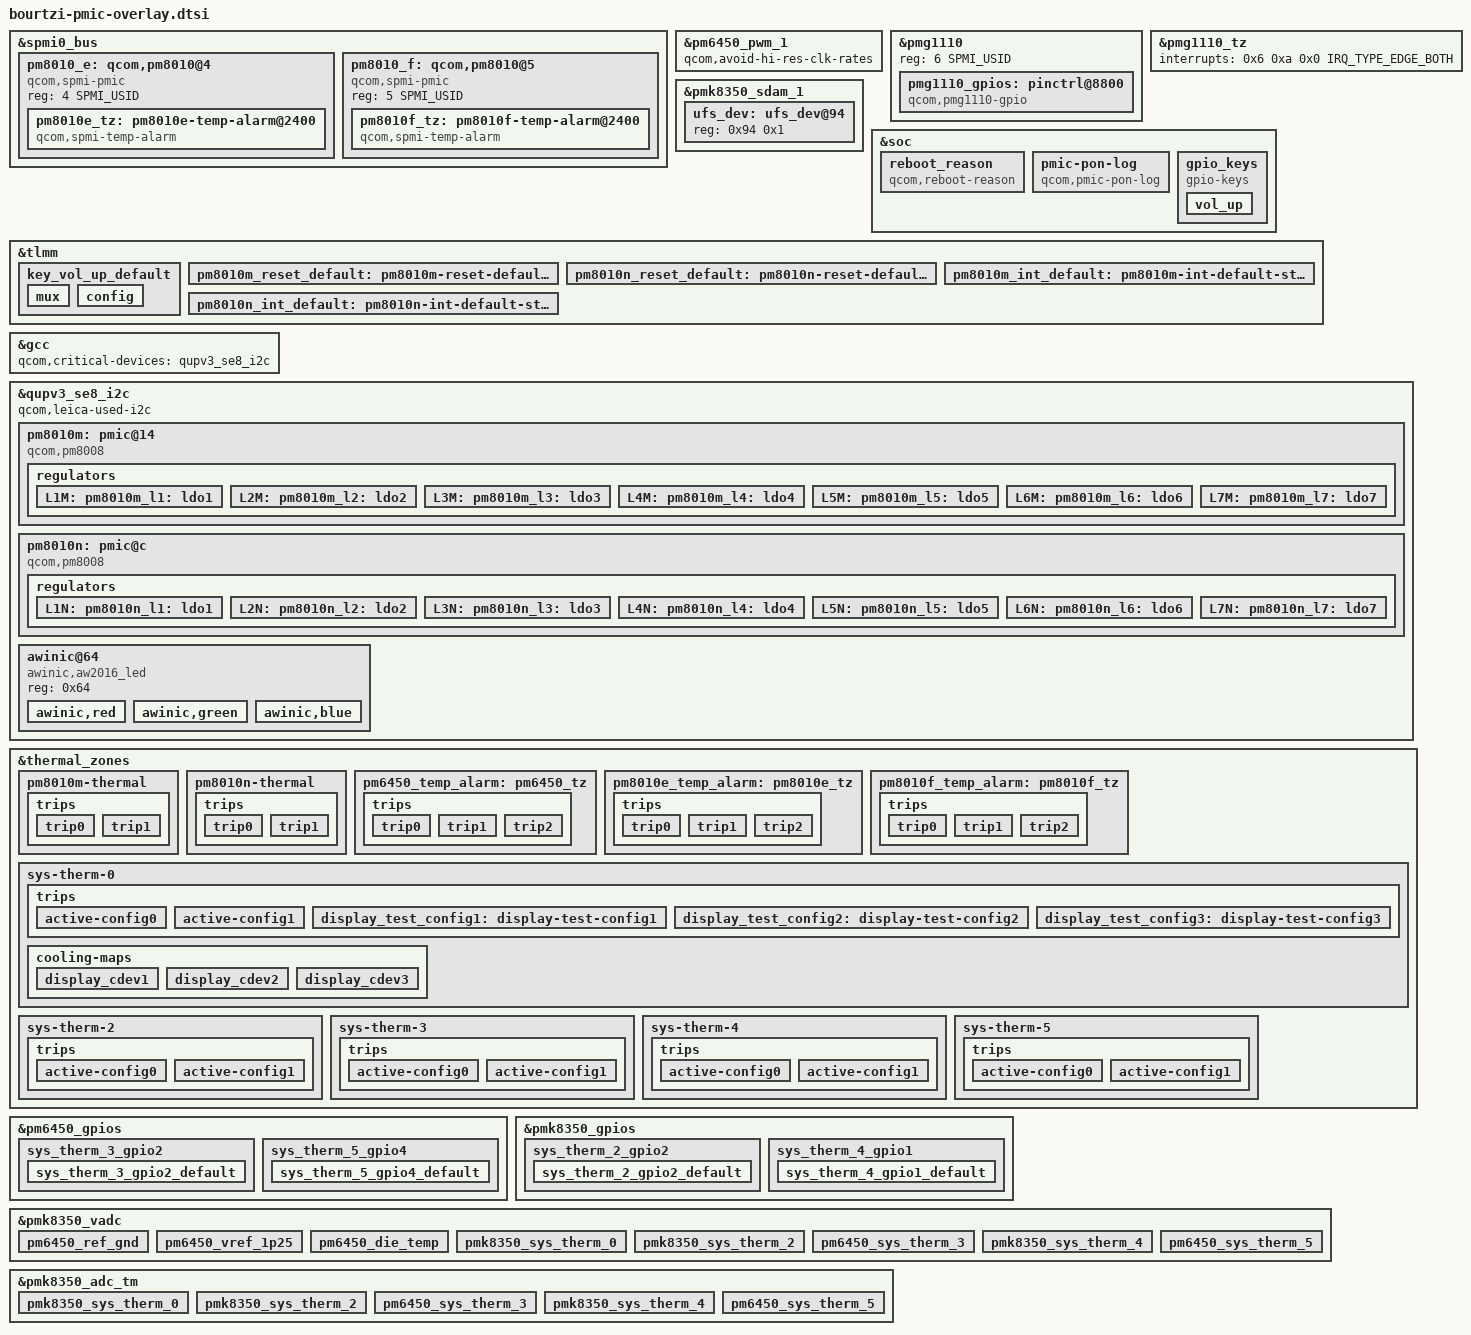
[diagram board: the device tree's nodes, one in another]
// SPDX-License-Identifier: BSD-3-Clause
/*
 * Copyright (c) Qualcomm Technologies, Inc. and/or its subsidiaries.
 */

#include <dt-bindings/gpio/gpio.h>
#include <dt-bindings/iio/qcom,spmi-adc7-pm6450.h>
#include <dt-bindings/interrupt-controller/irq.h>
#include <dt-bindings/pinctrl/qcom,pmic-gpio.h>

#include "pmk8350.dtsi"

&spmi0_bus {
	#include "pm6450.dtsi"
	#include "pmg1110.dtsi"

	pm8010_e: qcom,pm8010@4 {
		compatible = "qcom,spmi-pmic";
		reg = <4 SPMI_USID>;
		#address-cells = <1>;
		#size-cells = <0>;

		pm8010e_tz: pm8010e-temp-alarm@2400 {
			compatible = "qcom,spmi-temp-alarm";
			reg = <0x2400>;
			interrupts = <0x4 0x24 0x0 IRQ_TYPE_EDGE_BOTH>;
			#thermal-sensor-cells = <0>;
		};
	};

	pm8010_f: qcom,pm8010@5 {
		compatible = "qcom,spmi-pmic";
		reg = <5 SPMI_USID>;
		#address-cells = <1>;
		#size-cells = <0>;

		pm8010f_tz: pm8010f-temp-alarm@2400 {
			compatible = "qcom,spmi-temp-alarm";
			reg = <0x2400>;
			interrupts = <0x5 0x24 0x0 IRQ_TYPE_EDGE_BOTH>;
			#thermal-sensor-cells = <0>;
		};
	};
};

&pm6450_pwm_1 {
	status = "okay";
	qcom,avoid-hi-res-clk-rates;
};

&pmg1110 {
	reg = <6 SPMI_USID>;

	pmg1110_gpios: pinctrl@8800 {
		compatible = "qcom,pmg1110-gpio";
		reg = <0x8800>;
		gpio-controller;
		#gpio-cells = <2>;
		interrupt-controller;
		#interrupt-cells = <2>;
	};
};

&pmg1110_tz {
	interrupts = <0x6 0xa 0x0 IRQ_TYPE_EDGE_BOTH>;
};

&pmk8350_sdam_1 {
	ufs_dev: ufs_dev@94 {
		reg = <0x94 0x1>;
	 };
};

&soc {
	reboot_reason {
		compatible = "qcom,reboot-reason";
		nvmem-cells = <&restart_reason>;
		nvmem-cell-names = "restart_reason";
	};

	pmic-pon-log {
		compatible = "qcom,pmic-pon-log";
		nvmem = <&pmk8350_sdam_5>;
		nvmem-names = "pon_log";
	};

	gpio_keys {
		compatible = "gpio-keys";
		label = "gpio-keys";

		pinctrl-names = "default";
		pinctrl-0 = <&key_vol_up_default>;

		vol_up {
			label = "volume_up";
			gpios = <&tlmm 53 GPIO_ACTIVE_LOW>;
			linux,input-type = <1>;
			linux,code = <KEY_VOLUMEUP>;
			gpio-key,wakeup;
			debounce-interval = <15>;
			linux,can-disable;
		};
	};
};

&tlmm {
	key_vol_up_default: key_vol_up_default {
		mux {
			pins = "gpio53";
			function = "gpio";
		};

		config {
			pins = "gpio53";
			drive-strength = <2>;
			bias-pull-up;
			input-enable;
		};
	};

	pm8010m_reset_default: pm8010m-reset-default-state {
		pins = "gpio59";
		function = "gpio";
		bias-pull-down;
	};

	pm8010n_reset_default: pm8010n-reset-default-state {
		pins = "gpio30";
		function = "gpio";
		bias-pull-down;
	};

	pm8010m_int_default: pm8010m-int-default-state {
		pins = "gpio62";
		function = "gpio";
		drive-strength = <2>;
		bias-disable;
	};

	pm8010n_int_default: pm8010n-int-default-state {
		pins = "gpio28";
		function = "gpio";
		drive-strength = <2>;
		bias-disable;
	};
};

&gcc {
	qcom,critical-devices = <&qupv3_se8_i2c>;
};

&qupv3_se8_i2c {
	#address-cells = <1>;
	#size-cells = <0>;
	status = "okay";
	qcom,leica-used-i2c;

	pm8010m: pmic@14 {
		compatible = "qcom,pm8008";
		reg = <0x14>;

		interrupts-extended = <&tlmm 62 IRQ_TYPE_EDGE_RISING>;
		reset-gpios = <&tlmm 59 GPIO_ACTIVE_LOW>;

		pinctrl-names = "default";
		pinctrl-0 = <&pm8010m_int_default>, <&pm8010m_reset_default>;

		gpio-controller;
		#gpio-cells = <2>;
		gpio-ranges = <&pm8010m 0 0 2>;

		interrupt-controller;
		#interrupt-cells = <2>;

		#thermal-sensor-cells = <0>;

		regulators {
			L1M: pm8010m_l1: ldo1 {
				regulator-name = "pm8010m_l1";
				regulator-min-microvolt = <1056000>;
				regulator-max-microvolt = <1184000>;
			};

			L2M: pm8010m_l2: ldo2 {
				regulator-name = "pm8010m_l2";
				regulator-min-microvolt = <952000>;
				regulator-max-microvolt = <1152000>;
			};

			L3M: pm8010m_l3: ldo3 {
				regulator-name = "pm8010m_l3";
				regulator-min-microvolt = <2704000>;
				regulator-max-microvolt = <2904000>;
			};

			L4M: pm8010m_l4: ldo4 {
				regulator-name = "pm8010m_l4";
				regulator-min-microvolt = <2704000>;
				regulator-max-microvolt = <2904000>;
			};

			L5M: pm8010m_l5: ldo5 {
				regulator-name = "pm8010m_l5";
				regulator-min-microvolt = <1504000>;
				regulator-max-microvolt = <3544000>;
			};

			L6M: pm8010m_l6: ldo6 {
				regulator-name = "pm8010m_l6";
				regulator-min-microvolt = <2704000>;
				regulator-max-microvolt = <2904000>;
			};

			L7M: pm8010m_l7: ldo7 {
				regulator-name = "pm8010m_l7";
				regulator-min-microvolt = <2704000>;
				regulator-max-microvolt = <3000000>;
			};
		};
	};

	pm8010n: pmic@c {
		compatible = "qcom,pm8008";
		reg = <0xc>;

		interrupts-extended = <&tlmm 28 IRQ_TYPE_EDGE_RISING>;
		reset-gpios = <&tlmm 30 GPIO_ACTIVE_LOW>;

		pinctrl-names = "default";
		pinctrl-0 = <&pm8010n_int_default>, <&pm8010n_reset_default>;

		gpio-controller;
		#gpio-cells = <2>;
		gpio-ranges = <&pm8010n 0 0 2>;

		interrupt-controller;
		#interrupt-cells = <2>;

		#thermal-sensor-cells = <0>;

		regulators {
			L1N: pm8010n_l1: ldo1 {
				regulator-name = "pm8010n_l1";
				regulator-min-microvolt = <1056000>;
				regulator-max-microvolt = <1200000>;
			};

			L2N: pm8010n_l2: ldo2 {
				regulator-name = "pm8010n_l2";
				regulator-min-microvolt = <952000>;
				regulator-max-microvolt = <1152000>;
			};

			L3N: pm8010n_l3: ldo3 {
				regulator-name = "pm8010n_l3";
				regulator-min-microvolt = <1792000>;
				regulator-max-microvolt = <1904000>;
			};

			L4N: pm8010n_l4: ldo4 {
				regulator-name = "pm8010n_l4";
				regulator-min-microvolt = <1792000>;
				regulator-max-microvolt = <1904000>;
			};

			L5N: pm8010n_l5: ldo5 {
				regulator-name = "pm8010n_l5";
				regulator-min-microvolt = <1504000>;
				regulator-max-microvolt = <3544000>;
			};

			L6N: pm8010n_l6: ldo6 {
				regulator-name = "pm8010n_l6";
				regulator-min-microvolt = <2704000>;
				regulator-max-microvolt = <2904000>;
			};

			L7N: pm8010n_l7: ldo7 {
				regulator-name = "pm8010n_l7";
				regulator-min-microvolt = <1504000>;
				regulator-max-microvolt = <3544000>;
			};
		};
	};

	awinic@64 {
		compatible = "awinic,aw2016_led";
		reg = <0x64>;

		awinic,red {
			awinic,name = "red";
			awinic,id = <0>;
			awinic,imax = <2>;
			awinic,led-current = <3>;
			awinic,max-brightness = <255>;
			awinic,rise-time-ms = <6>;
			awinic,hold-time-ms = <0>;
			awinic,fall-time-ms = <6>;
			awinic,off-time-ms = <4>;
		};

		awinic,green {
			awinic,name = "green";
			awinic,id = <1>;
			awinic,imax = <2>;
			awinic,led-current = <3>;
			awinic,max-brightness = <255>;
			awinic,rise-time-ms = <6>;
			awinic,hold-time-ms = <0>;
			awinic,fall-time-ms = <6>;
			awinic,off-time-ms = <4>;
		};

		awinic,blue {
			awinic,name = "blue";
			awinic,id = <2>;
			awinic,imax = <2>;
			awinic,led-current = <3>;
			awinic,max-brightness = <255>;
			awinic,rise-time-ms = <6>;
			awinic,hold-time-ms = <0>;
			awinic,fall-time-ms = <6>;
			awinic,off-time-ms = <4>;
		};
	};
};

&thermal_zones {
	pm8010m-thermal {
		polling-delay-passive = <100>;
		polling-delay = <0>;
		thermal-sensors = <&pm8010m>;

		trips {
			trip0 {
				temperature = <95000>;
				hysteresis = <0>;
				type = "passive";
			};

			trip1 {
				temperature = <115000>;
				hysteresis = <0>;
				type = "critical";
			};
		};
	};

	pm8010n-thermal {
		polling-delay-passive = <100>;
		polling-delay = <0>;
		thermal-sensors = <&pm8010n>;

		trips {
			trip0 {
				temperature = <95000>;
				hysteresis = <0>;
				type = "passive";
			};

			trip1 {
				temperature = <115000>;
				hysteresis = <0>;
				type = "critical";
			};
		};
	};

	pm6450_temp_alarm: pm6450_tz {
		polling-delay-passive = <100>;
		thermal-sensors = <&pm6450_tz>;

		trips {
			trip0 {
				temperature = <95000>;
				hysteresis = <0>;
				type = "passive";
			};

			trip1 {
				temperature = <115000>;
				hysteresis = <0>;
				type = "hot";
			};

			trip2 {
				temperature = <145000>;
				hysteresis = <0>;
				type = "critical";
			};
		};
	};

	pm8010e_temp_alarm: pm8010e_tz {
		polling-delay-passive = <100>;
		thermal-sensors = <&pm8010e_tz>;

		trips {
			trip0 {
				temperature = <95000>;
				hysteresis = <0>;
				type = "passive";
			};

			trip1 {
				temperature = <115000>;
				hysteresis = <0>;
				type = "hot";
			};

			trip2 {
				temperature = <145000>;
				hysteresis = <0>;
				type = "critical";
			};
		};
	};

	pm8010f_temp_alarm: pm8010f_tz {
		polling-delay-passive = <100>;
		thermal-sensors = <&pm8010f_tz>;

		trips {
			trip0 {
				temperature = <95000>;
				hysteresis = <0>;
				type = "passive";
			};

			trip1 {
				temperature = <115000>;
				hysteresis = <0>;
				type = "hot";
			};

			trip2 {
				temperature = <145000>;
				hysteresis = <0>;
				type = "critical";
			};
		};
	};

	sys-therm-0 {
		polling-delay-passive = <0>;
		thermal-sensors = <&pmk8350_adc_tm 0>;

		trips {
			active-config0 {
				temperature = <125000>;
				hysteresis = <1000>;
				type = "passive";
			};

			active-config1 {
				temperature = <125000>;
				hysteresis = <1000>;
				type = "passive";
			};

			display_test_config1: display-test-config1 {
				temperature = <125000>;
				hysteresis = <1000>;
				type = "passive";
			};

			display_test_config2: display-test-config2 {
				temperature = <125000>;
				hysteresis = <1000>;
				type = "passive";
			};

			display_test_config3: display-test-config3 {
				temperature = <125000>;
				hysteresis = <1000>;
				type = "passive";
			};
		};

		cooling-maps {
			display_cdev1 {
				trip = <&display_test_config1>;
				cooling-device = <&display_fps 1 1>;
			};

			display_cdev2 {
				trip = <&display_test_config2>;
				cooling-device = <&display_fps 2 2>;
			};

			display_cdev3 {
				trip = <&display_test_config3>;
				cooling-device = <&display_fps 3 3>;
			};
		};
	};

	sys-therm-2 {
		polling-delay-passive = <0>;
		thermal-sensors = <&pmk8350_adc_tm 2>;

		trips {
			active-config0 {
				temperature = <125000>;
				hysteresis = <1000>;
				type = "passive";
			};

			active-config1 {
				temperature = <125000>;
				hysteresis = <1000>;
				type = "passive";
			};
		};
	};

	sys-therm-3 {
		polling-delay-passive = <0>;
		thermal-sensors = <&pmk8350_adc_tm 3>;

		trips {
			active-config0 {
				temperature = <125000>;
				hysteresis = <1000>;
				type = "passive";
			};

			active-config1 {
				temperature = <125000>;
				hysteresis = <1000>;
				type = "passive";
			};
		};
	};

	sys-therm-4 {
		polling-delay-passive = <0>;
		thermal-sensors = <&pmk8350_adc_tm 4>;

		trips {
			active-config0 {
				temperature = <125000>;
				hysteresis = <1000>;
				type = "passive";
			};

			active-config1 {
				temperature = <125000>;
				hysteresis = <1000>;
				type = "passive";
			};
		};
	};

	sys-therm-5 {
		polling-delay-passive = <0>;
		thermal-sensors = <&pmk8350_adc_tm 5>;

		trips {
			active-config0 {
				temperature = <125000>;
				hysteresis = <1000>;
				type = "passive";
			};

			active-config1 {
				temperature = <125000>;
				hysteresis = <1000>;
				type = "passive";
			};
		};
	};
};

&pm6450_gpios {
	sys_therm_3_gpio2 {
		sys_therm_3_gpio2_default: sys_therm_3_gpio2_default {
			pins = "gpio2";
			bias-high-impedance;
		};
	};

	sys_therm_5_gpio4 {
		sys_therm_5_gpio4_default: sys_therm_5_gpio4_default {
			pins = "gpio4";
			bias-high-impedance;
		};
	};
};

&pmk8350_gpios {
	sys_therm_2_gpio2 {
		sys_therm_2_gpio2_default: sys_therm_2_gpio2_default {
			pins = "gpio2";
			bias-high-impedance;
		};
	};

	sys_therm_4_gpio1 {
		sys_therm_4_gpio1_default: sys_therm_4_gpio1_default {
			pins = "gpio1";
			bias-high-impedance;
		};
	};
};

&pmk8350_vadc {
	pinctrl-names = "default";
	pinctrl-0 = <&sys_therm_2_gpio2_default>,
		    <&sys_therm_3_gpio2_default>,
		    <&sys_therm_4_gpio1_default>,
		    <&sys_therm_5_gpio4_default>;

	/delete-node/ pmk8350_xo_therm;
	/delete-node/ pm8350_ref_gnd;
	/delete-node/ pm8350_vref_1p25;
	/delete-node/ pm8350_die_temp;
	/delete-node/ pm8350_vph_pwr;

	/delete-node/ pm8350b_ref_gnd;
	/delete-node/ pm8350b_vref_1p25;
	/delete-node/ pm8350b_die_temp;
	/delete-node/ pm8350b_vph_pwr;
	/delete-node/ pm8350b_vbat_sns;

	/delete-node/ pmr735a_ref_gnd;
	/delete-node/ pmr735a_vref_1p25;
	/delete-node/ pmr735a_die_temp;

	/delete-node/ pmr735b_ref_gnd;
	/delete-node/ pmr735b_vref_1p25;
	/delete-node/ pmr735b_die_temp;

	/* PM6450 Channel nodes */
	pm6450_ref_gnd {
		reg = <PM6450_ADC7_REF_GND>;
		label = "pm6450_ref_gnd";
		qcom,pre-scaling = <1 1>;
	};

	pm6450_vref_1p25 {
		reg = <PM6450_ADC7_1P25VREF>;
		label = "pm6450_vref_1p25";
		qcom,pre-scaling = <1 1>;
	};

	pm6450_die_temp {
		reg = <PM6450_ADC7_DIE_TEMP>;
		label = "pm6450_die_temp";
		qcom,pre-scaling = <1 1>;
	};

	pmk8350_sys_therm_0 {
		reg = <PMK8350_ADC7_AMUX_THM1_100K_PU>;
		label = "pmk8350_sys_therm_0";
		qcom,ratiometric;
		qcom,hw-settle-time = <200>;
		qcom,pre-scaling = <1 1>;
	};

	pmk8350_sys_therm_2 {
		reg = <PMK8350_ADC7_AMUX_THM3_100K_PU>;
		label = "pmk8350_sys_therm_2";
		qcom,ratiometric;
		qcom,hw-settle-time = <200>;
		qcom,pre-scaling = <1 1>;
	};

	pm6450_sys_therm_3 {
		reg = <PM6450_ADC7_AMUX1_GPIO2_100K_PU>;
		label = "pm6450_sys_therm_3";
		qcom,ratiometric;
		qcom,hw-settle-time = <200>;
		qcom,pre-scaling = <1 1>;
	};

	pmk8350_sys_therm_4 {
		reg = <PMK8350_ADC7_AMUX_THM2_100K_PU>;
		label = "pmk8350_sys_therm_4";
		qcom,ratiometric;
		qcom,hw-settle-time = <200>;
		qcom,pre-scaling = <1 1>;
	};

	pm6450_sys_therm_5 {
		reg = <PM6450_ADC7_AMUX3_GPIO4_100K_PU>;
		label = "pm6450_sys_therm_5";
		qcom,ratiometric;
		qcom,hw-settle-time = <200>;
		qcom,pre-scaling = <1 1>;
	};
};

&pmk8350_adc_tm {
	pmk8350_sys_therm_0 {
		reg = <0>;
		io-channels = <&pmk8350_vadc PMK8350_ADC7_AMUX_THM1_100K_PU>;
		qcom,ratiometric;
		qcom,hw-settle-time-us = <200>;
	};

	pmk8350_sys_therm_2 {
		reg = <2>;
		io-channels = <&pmk8350_vadc PMK8350_ADC7_AMUX_THM3_100K_PU>;
		qcom,ratiometric;
		qcom,hw-settle-time-us = <200>;
	};

	pm6450_sys_therm_3 {
		reg = <3>;
		io-channels = <&pmk8350_vadc PM6450_ADC7_AMUX1_GPIO2_100K_PU>;
		qcom,ratiometric;
		qcom,hw-settle-time-us = <200>;
	};

	pmk8350_sys_therm_4 {
		reg = <4>;
		io-channels = <&pmk8350_vadc PMK8350_ADC7_AMUX_THM2_100K_PU>;
		qcom,ratiometric;
		qcom,hw-settle-time-us = <200>;
	};

	pm6450_sys_therm_5 {
		reg = <5>;
		io-channels = <&pmk8350_vadc PM6450_ADC7_AMUX3_GPIO4_100K_PU>;
		qcom,ratiometric;
		qcom,hw-settle-time-us = <200>;
	};
};
